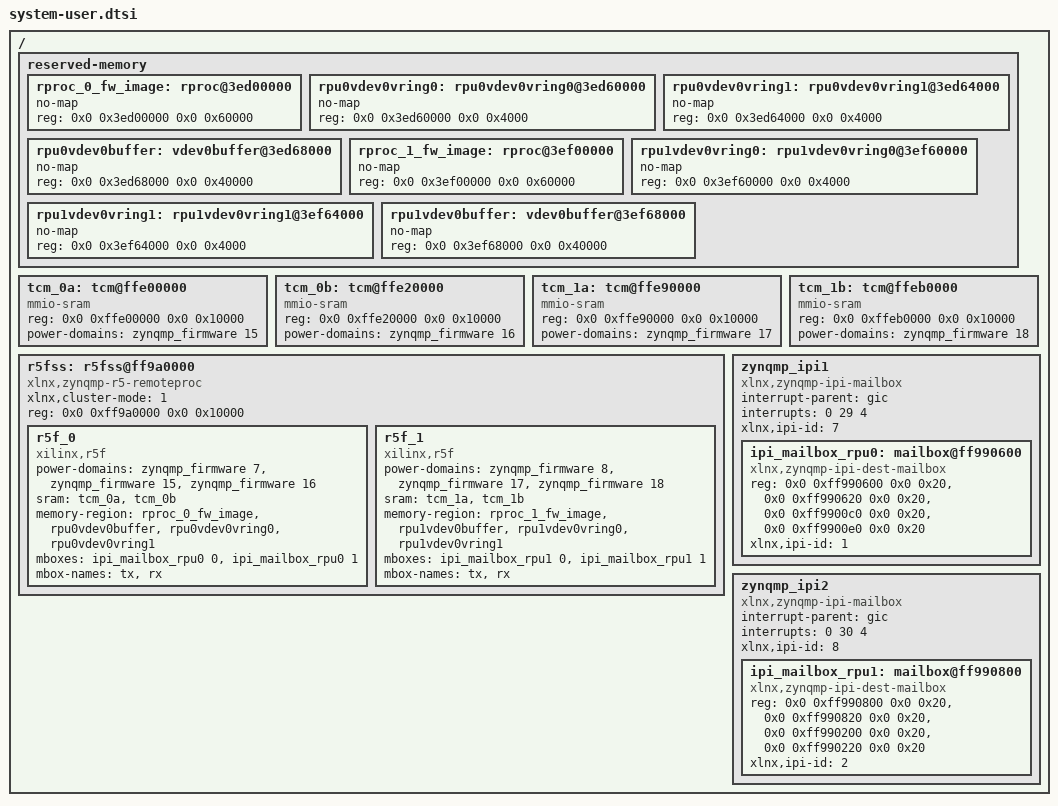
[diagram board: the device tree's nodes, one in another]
/include/ "system-conf.dtsi"

/ {
	/*
	 * AMD Vitis 2024.2 OpenAMP ZynqMP layout. The firmware carveouts,
	 * vrings, and shared buffers must stay synchronized with the Vitis
	 * platform generated from openamp-overlay-zynqmp.yaml.
	 */
	reserved-memory {
		#address-cells = <2>;
		#size-cells = <2>;
		ranges;

		rproc_0_fw_image: rproc@3ed00000 {
			no-map;
			reg = <0x0 0x3ed00000 0x0 0x60000>;
		};

		rpu0vdev0vring0: rpu0vdev0vring0@3ed60000 {
			no-map;
			/* 256 descriptors at 4 KiB alignment require 0x3000 bytes. */
			reg = <0x0 0x3ed60000 0x0 0x4000>;
		};

		rpu0vdev0vring1: rpu0vdev0vring1@3ed64000 {
			no-map;
			reg = <0x0 0x3ed64000 0x0 0x4000>;
		};

		rpu0vdev0buffer: vdev0buffer@3ed68000 {
			no-map;
			reg = <0x0 0x3ed68000 0x0 0x40000>;
		};

		rproc_1_fw_image: rproc@3ef00000 {
			no-map;
			reg = <0x0 0x3ef00000 0x0 0x60000>;
		};

		rpu1vdev0vring0: rpu1vdev0vring0@3ef60000 {
			no-map;
			reg = <0x0 0x3ef60000 0x0 0x4000>;
		};

		rpu1vdev0vring1: rpu1vdev0vring1@3ef64000 {
			no-map;
			reg = <0x0 0x3ef64000 0x0 0x4000>;
		};

		rpu1vdev0buffer: vdev0buffer@3ef68000 {
			no-map;
			reg = <0x0 0x3ef68000 0x0 0x40000>;
		};
	};

	/* TCM banks consumed through the 2024.2 zynqmp_r5_remoteproc driver. */
	tcm_0a: tcm@ffe00000 {
		compatible = "mmio-sram";
		reg = <0x0 0xffe00000 0x0 0x10000>;
		power-domains = <&zynqmp_firmware 15>; /* PD_TCM_0_A */
	};

	tcm_0b: tcm@ffe20000 {
		compatible = "mmio-sram";
		reg = <0x0 0xffe20000 0x0 0x10000>;
		power-domains = <&zynqmp_firmware 16>; /* PD_TCM_0_B */
	};

	tcm_1a: tcm@ffe90000 {
		compatible = "mmio-sram";
		reg = <0x0 0xffe90000 0x0 0x10000>;
		power-domains = <&zynqmp_firmware 17>; /* PD_TCM_1_A */
	};

	tcm_1b: tcm@ffeb0000 {
		compatible = "mmio-sram";
		reg = <0x0 0xffeb0000 0x0 0x10000>;
		power-domains = <&zynqmp_firmware 18>; /* PD_TCM_1_B */
	};

	r5fss: r5fss@ff9a0000 {
		compatible = "xlnx,zynqmp-r5-remoteproc";
		/* linux-xlnx 6.6.40: 0 = lockstep, 1 = split. */
		xlnx,cluster-mode = <1>;
		#address-cells = <2>;
		#size-cells = <2>;
		ranges;
		reg = <0x0 0xff9a0000 0x0 0x10000>;

		r5f_0: r5f_0 {
			compatible = "xilinx,r5f";
			/* PD_RPU_0, PD_TCM_0_A, PD_TCM_0_B */
			power-domains = <&zynqmp_firmware 7>,
					<&zynqmp_firmware 15>,
					<&zynqmp_firmware 16>;
			sram = <&tcm_0a>, <&tcm_0b>;
			memory-region = <&rproc_0_fw_image>,
					<&rpu0vdev0buffer>,
					<&rpu0vdev0vring0>,
					<&rpu0vdev0vring1>;
			mboxes = <&ipi_mailbox_rpu0 0>,
				 <&ipi_mailbox_rpu0 1>;
			mbox-names = "tx", "rx";
		};

		r5f_1: r5f_1 {
			compatible = "xilinx,r5f";
			/* PD_RPU_1, PD_TCM_1_A, PD_TCM_1_B */
			power-domains = <&zynqmp_firmware 8>,
					<&zynqmp_firmware 17>,
					<&zynqmp_firmware 18>;
			sram = <&tcm_1a>, <&tcm_1b>;
			memory-region = <&rproc_1_fw_image>,
					<&rpu1vdev0buffer>,
					<&rpu1vdev0vring0>,
					<&rpu1vdev0vring1>;
			mboxes = <&ipi_mailbox_rpu1 0>,
				 <&ipi_mailbox_rpu1 1>;
			mbox-names = "tx", "rx";
		};
	};

	zynqmp_ipi1 {
		compatible = "xlnx,zynqmp-ipi-mailbox";
		interrupt-parent = <&gic>;
		interrupts = <0 29 4>;
		xlnx,ipi-id = <7>;
		#address-cells = <2>;
		#size-cells = <2>;
		ranges;

		ipi_mailbox_rpu0: mailbox@ff990600 {
			compatible = "xlnx,zynqmp-ipi-dest-mailbox";
			reg = <0x0 0xff990600 0x0 0x20>,
			      <0x0 0xff990620 0x0 0x20>,
			      <0x0 0xff9900c0 0x0 0x20>,
			      <0x0 0xff9900e0 0x0 0x20>;
			reg-names = "local_request_region",
				    "local_response_region",
				    "remote_request_region",
				    "remote_response_region";
			#mbox-cells = <1>;
			xlnx,ipi-id = <1>;
		};
	};

	zynqmp_ipi2 {
		compatible = "xlnx,zynqmp-ipi-mailbox";
		interrupt-parent = <&gic>;
		interrupts = <0 30 4>;
		xlnx,ipi-id = <8>;
		#address-cells = <2>;
		#size-cells = <2>;
		ranges;

		ipi_mailbox_rpu1: mailbox@ff990800 {
			compatible = "xlnx,zynqmp-ipi-dest-mailbox";
			reg = <0x0 0xff990800 0x0 0x20>,
			      <0x0 0xff990820 0x0 0x20>,
			      <0x0 0xff990200 0x0 0x20>,
			      <0x0 0xff990220 0x0 0x20>;
			reg-names = "local_request_region",
				    "local_response_region",
				    "remote_request_region",
				    "remote_response_region";
			#mbox-cells = <1>;
			xlnx,ipi-id = <2>;
		};
	};
};
